VERSION ""

NS_ :

BS_ :

BU_ :

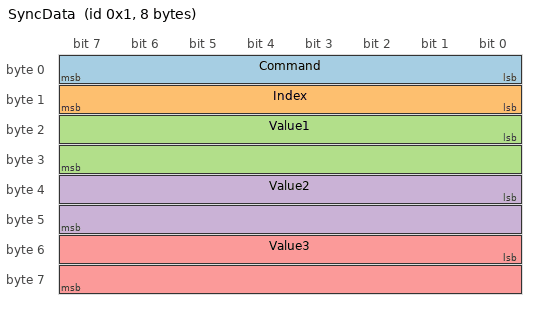
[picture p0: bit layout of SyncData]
BO_ 1 SyncData: 8 Vector__XXX
  SG_ Command : 0|8@1+ (1,0) [0|1000] "" Vector__XXX
  SG_ Index : 8|8@1+ (1,0) [0|1000] "" Vector__XXX
  SG_ Value1 : 16|16@1- (1,0) [-2147473647|2147473647] "" Vector__XXX
  SG_ Value2 : 32|16@1- (1,0) [-2147473647|2147473647] "" Vector__XXX
  SG_ Value3 : 48|16@1- (1,0) [-2147473647|2147473647] "" Vector__XXX

BA_DEF_ "DBName" STRING;
BA_DEF_ "BusType" STRING;
BA_DEF_ BO_ "VFrameFormat" ENUM "StandardCAN","ExtendedCAN","reserved","J1939PG","reserved","reserved","reserved","reserved","reserved","reserved","reserved","reserved","reserved","reserved","StandardCAN_FD","ExtendedCAN_FD";
BA_DEF_ BO_ "GenMsgSendType" ENUM "Cyclic","Event","CyclicIfActive","SpontanWithDelay","CyclicAndSpontan","CyclicAndSpontanWithDelay";
BA_DEF_ BO_ "GenMsgCycleTime" INT 0 0;
BA_DEF_DEF_ "DBName" "MW_AHRSv1";
BA_DEF_DEF_ "BusType" "CAN";
BA_DEF_DEF_ "VFrameFormat" "StandardCAN";
BA_DEF_DEF_ "GenMsgSendType" "Cyclic";
BA_DEF_DEF_ "GenMsgCycleTime" 0;
BA_ "GenMsgCycleTime" BO_ 1 10;
